AUTOSAR XML (schema 00044)
package /ComponentTypes
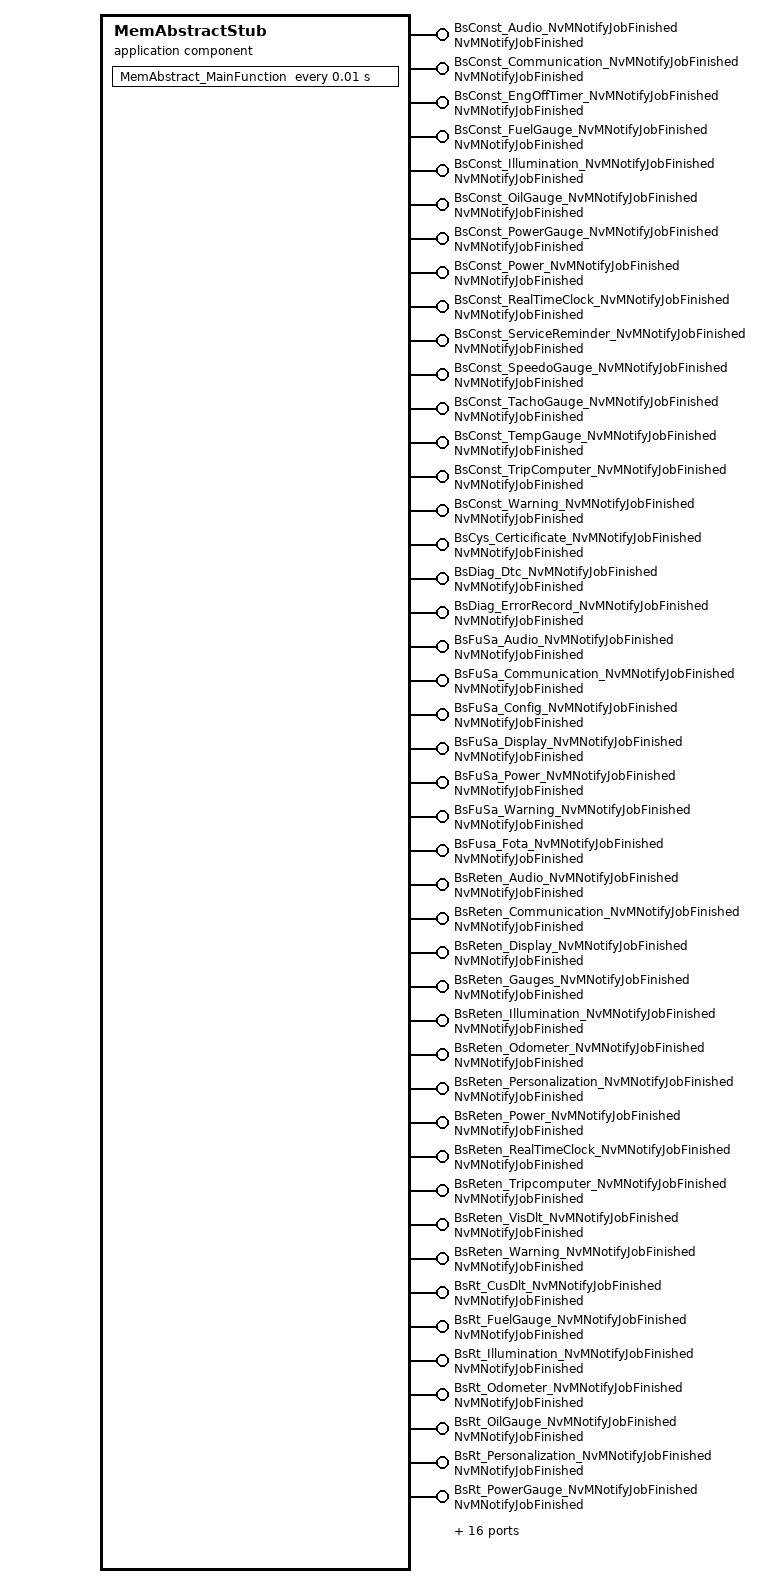
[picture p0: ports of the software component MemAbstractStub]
  application sw component type MemAbstractStub
    60 x provide port, all with server-com-spec{operation=JobFinished, queue-length=1}, provided-interface=NvMNotifyJobFinished:
      BsConst_Audio_NvMNotifyJobFinished
      BsConst_Communication_NvMNotifyJobFinished
      BsConst_EngOffTimer_NvMNotifyJobFinished
      BsConst_FuelGauge_NvMNotifyJobFinished
      BsConst_Illumination_NvMNotifyJobFinished
      BsConst_OilGauge_NvMNotifyJobFinished
      BsConst_PowerGauge_NvMNotifyJobFinished
      BsConst_Power_NvMNotifyJobFinished
      BsConst_RealTimeClock_NvMNotifyJobFinished
      BsConst_ServiceReminder_NvMNotifyJobFinished
      BsConst_SpeedoGauge_NvMNotifyJobFinished
      BsConst_TachoGauge_NvMNotifyJobFinished
      BsConst_TempGauge_NvMNotifyJobFinished
      BsConst_TripComputer_NvMNotifyJobFinished
      BsConst_Warning_NvMNotifyJobFinished
      BsCys_Certicificate_NvMNotifyJobFinished
      BsDiag_Dtc_NvMNotifyJobFinished
      BsDiag_ErrorRecord_NvMNotifyJobFinished
      BsFuSa_Audio_NvMNotifyJobFinished
      BsFuSa_Communication_NvMNotifyJobFinished
      BsFuSa_Config_NvMNotifyJobFinished
      BsFuSa_Display_NvMNotifyJobFinished
      BsFuSa_Power_NvMNotifyJobFinished
      BsFuSa_Warning_NvMNotifyJobFinished
      BsFusa_Fota_NvMNotifyJobFinished
      BsReten_Audio_NvMNotifyJobFinished
      BsReten_Communication_NvMNotifyJobFinished
      BsReten_Display_NvMNotifyJobFinished
      BsReten_Gauges_NvMNotifyJobFinished
      BsReten_Illumination_NvMNotifyJobFinished
      BsReten_Odometer_NvMNotifyJobFinished
      BsReten_Personalization_NvMNotifyJobFinished
      BsReten_Power_NvMNotifyJobFinished
      BsReten_RealTimeClock_NvMNotifyJobFinished
      BsReten_Tripcomputer_NvMNotifyJobFinished
      BsReten_VisDlt_NvMNotifyJobFinished
      BsReten_Warning_NvMNotifyJobFinished
      BsRt_CusDlt_NvMNotifyJobFinished
      BsRt_FuelGauge_NvMNotifyJobFinished
      BsRt_Illumination_NvMNotifyJobFinished
      BsRt_Odometer_NvMNotifyJobFinished
      BsRt_OilGauge_NvMNotifyJobFinished
      BsRt_Personalization_NvMNotifyJobFinished
      BsRt_PowerGauge_NvMNotifyJobFinished
      BsRt_RealTimeClock_NvMNotifyJobFinished
      BsRt_SpeedoGauge_NvMNotifyJobFinished
      BsRt_TachoGauge_NvMNotifyJobFinished
      BsRt_TempGauge_NvMNotifyJobFinished
      BsRt_TripComputer_NvMNotifyJobFinished
      BsRt_Warning_NvMNotifyJobFinished
      BsShare_EcuPartNumber_NvMNotifyJobFinished
      BsShare_SwUpdFotaFinPrint_NvMNotifyJobFinished
      BsShare_SwUpdFotaMode_NvMNotifyJobFinished
      BsShare_SwUpdFotaStatus_NvMNotifyJobFinished
      BsShare_SwUpdFotadecrypt_NvMNotifyJobFinished
      BsShare_SwUpdReflash_NvMNotifyJobFinished
      BsShare_VehicleConfig_NvMNotifyJobFinished
      BsShare_VisMeet_NvMNotifyJobFinished
      RefCys_Certicificate1_NvMNotifyJobFinished
      RefCys_Certicificate_NvMNotifyJobFinished
    60 x provide/require port:
      BsConst_PowerGauge_Element: nv-provide-com-spec{ram-block-init-value=64 x 0, rom-block-init-value=64 x 0, variable=Value}, nv-require-com-spec{init-value=64 x 0, variable=Value}, provided-required-interface=BsConst_PowerGauge_Element
      BsFuSa_Audio_Element: nv-provide-com-spec{ram-block-init-value=32 x 0, rom-block-init-value=32 x 0, variable=Value}, nv-require-com-spec{init-value=32 x 0, variable=Value}, provided-required-interface=BsFuSa_Audio_Element
      BsReten_Odometer_Element: nv-provide-com-spec{ram-block-init-value=100 x 0, rom-block-init-value=100 x 0, variable=Value}, nv-require-com-spec{init-value=100 x 0, variable=Value}, provided-required-interface=BsReten_Odometer_Element
      BsDiag_ErrorRecord_Element: nv-provide-com-spec{ram-block-init-value=1024 x 0, rom-block-init-value=1024 x 0, variable=Value}, nv-require-com-spec{init-value=1024 x 0, variable=Value}, provided-required-interface=BsDiag_ErrorRecord_Element
      BsConst_Audio_Element: nv-provide-com-spec{ram-block-init-value=128 x 0, rom-block-init-value=128 x 0, variable=Value}, nv-require-com-spec{init-value=128 x 0, variable=Value}, provided-required-interface=BsConst_Audio_Element
      BsConst_TempGauge_Element: nv-provide-com-spec{ram-block-init-value=64 x 0, rom-block-init-value=64 x 0, variable=Value}, nv-require-com-spec{init-value=64 x 0, variable=Value}, provided-required-interface=BsConst_TempGauge_Element
      BsFuSa_Communication_Element: nv-provide-com-spec{ram-block-init-value=16 x 0, rom-block-init-value=16 x 0, variable=Value}, nv-require-com-spec{init-value=16 x 0, variable=Value}, provided-required-interface=BsFuSa_Communication_Element
      BsRt_CusDlt_Element: nv-provide-com-spec{ram-block-init-value=128 x 0, rom-block-init-value=128 x 0, variable=Value}, nv-require-com-spec{init-value=128 x 0, variable=Value}, provided-required-interface=BsRt_CusDlt_Element
      BsShare_SwUpdFotaFinPrint_Element: nv-provide-com-spec{ram-block-init-value=32 x 0, rom-block-init-value=32 x 0, variable=Value}, nv-require-com-spec{init-value=32 x 0, variable=Value}, provided-required-interface=BsShare_SwUpdFotaFinPrint_Element
      BsConst_Power_Element: nv-provide-com-spec{ram-block-init-value=32 x 0, rom-block-init-value=32 x 0, variable=Value}, nv-require-com-spec{init-value=32 x 0, variable=Value}, provided-required-interface=BsConst_Power_Element
      BsRt_Illumination_Element: nv-provide-com-spec{ram-block-init-value=100 x 0, rom-block-init-value=100 x 0, variable=Value}, nv-require-com-spec{init-value=100 x 0, variable=Value}, provided-required-interface=BsRt_Illumination_Element
      BsReten_Gauges_Element: nv-provide-com-spec{ram-block-init-value=100 x 0, rom-block-init-value=100 x 0, variable=Value}, nv-require-com-spec{init-value=100 x 0, variable=Value}, provided-required-interface=BsReten_Gauges_Element
      BsCys_Certicificate_Element: nv-provide-com-spec{ram-block-init-value=64 x 0, rom-block-init-value=64 x 0, variable=Value}, nv-require-com-spec{init-value=64 x 0, variable=Value}, provided-required-interface=BsCys_Certicificate_Element
      BsConst_Communication_Element: nv-provide-com-spec{ram-block-init-value=64 x 0, rom-block-init-value=64 x 0, variable=Value}, nv-require-com-spec{init-value=64 x 0, variable=Value}, provided-required-interface=BsConst_Communication_Element
      BsShare_EcuPartNumber_Element: nv-provide-com-spec{ram-block-init-value=128 x 0, rom-block-init-value=128 x 0, variable=Value}, nv-require-com-spec{init-value=128 x 0, variable=Value}, provided-required-interface=BsShare_EcuPartNumber_Element
      BsShare_SwUpdFotaStatus_Element: nv-provide-com-spec{ram-block-init-value=48 x 0, rom-block-init-value=48 x 0, variable=Value}, nv-require-com-spec{init-value=48 x 0, variable=Value}, provided-required-interface=BsShare_SwUpdFotaStatus_Element
      RefCys_Certicificate_Element: nv-provide-com-spec{ram-block-init-value=64 x 0, rom-block-init-value=64 x 0, variable=Value}, nv-require-com-spec{init-value=64 x 0, variable=Value}, provided-required-interface=RefCys_Certicificate_Element
      BsReten_Audio_Element: nv-provide-com-spec{ram-block-init-value=100 x 0, rom-block-init-value=100 x 0, variable=Value}, nv-require-com-spec{init-value=100 x 0, variable=Value}, provided-required-interface=BsReten_Audio_Element
      BsConst_OilGauge_Element: nv-provide-com-spec{ram-block-init-value=64 x 0, rom-block-init-value=64 x 0, variable=Value}, nv-require-com-spec{init-value=64 x 0, variable=Value}, provided-required-interface=BsConst_OilGauge_Element
      BsConst_TripComputer_Element: nv-provide-com-spec{ram-block-init-value=64 x 0, rom-block-init-value=64 x 0, variable=Value}, nv-require-com-spec{init-value=64 x 0, variable=Value}, provided-required-interface=BsConst_TripComputer_Element
      BsConst_FuelGauge_Element: nv-provide-com-spec{ram-block-init-value=128 x 0, rom-block-init-value=128 x 0, variable=Value}, nv-require-com-spec{init-value=128 x 0, variable=Value}, provided-required-interface=BsConst_FuelGauge_Element
      BsFusa_Fota_Element: nv-provide-com-spec{ram-block-init-value=32 x 0, rom-block-init-value=32 x 0, variable=Value}, nv-require-com-spec{init-value=32 x 0, variable=Value}, provided-required-interface=BsFusa_Fota_Element
      BsReten_Illumination_Element: nv-provide-com-spec{ram-block-init-value=100 x 0, rom-block-init-value=100 x 0, variable=Value}, nv-require-com-spec{init-value=100 x 0, variable=Value}, provided-required-interface=BsReten_Illumination_Element
      BsRt_PowerGauge_Element: nv-provide-com-spec{ram-block-init-value=32 x 0, rom-block-init-value=32 x 0, variable=Value}, nv-require-com-spec{init-value=32 x 0, variable=Value}, provided-required-interface=BsRt_PowerGauge_Element
      BsReten_Tripcomputer_Element: nv-provide-com-spec{ram-block-init-value=100 x 0, rom-block-init-value=100 x 0, variable=Value}, nv-require-com-spec{init-value=100 x 0, variable=Value}, provided-required-interface=BsReten_Tripcomputer_Element
      BsFuSa_Display_Element: nv-provide-com-spec{ram-block-init-value=64 x 0, rom-block-init-value=64 x 0, variable=Value}, nv-require-com-spec{init-value=64 x 0, variable=Value}, provided-required-interface=BsFuSa_Display_Element
      BsReten_Power_Element: nv-provide-com-spec{ram-block-init-value=100 x 0, rom-block-init-value=100 x 0, variable=Value}, nv-require-com-spec{init-value=100 x 0, variable=Value}, provided-required-interface=BsReten_Power_Element
      BsShare_SwUpdReflash_Element: nv-provide-com-spec{ram-block-init-value=8 x 0, rom-block-init-value=8 x 0, variable=Value}, nv-require-com-spec{init-value=8 x 0, variable=Value}, provided-required-interface=BsShare_SwUpdReflash_Element
      BsRt_Odometer_Element: nv-provide-com-spec{ram-block-init-value=128 x 0, rom-block-init-value=128 x 0, variable=Value}, nv-require-com-spec{init-value=128 x 0, variable=Value}, provided-required-interface=BsRt_Odometer_Element
      BsShare_SwUpdFotadecrypt_Element: nv-provide-com-spec{ram-block-init-value=64 x 0, rom-block-init-value=64 x 0, variable=Value}, nv-require-com-spec{init-value=64 x 0, variable=Value}, provided-required-interface=BsShare_SwUpdFotadecrypt_Element
      BsConst_EngOffTimer_Element: nv-provide-com-spec{ram-block-init-value=32 x 0, rom-block-init-value=32 x 0, variable=Value}, nv-require-com-spec{init-value=32 x 0, variable=Value}, provided-required-interface=BsConst_EngOffTimer_Element
      BsReten_RealTimeClock_Element: nv-provide-com-spec{ram-block-init-value=100 x 0, rom-block-init-value=100 x 0, variable=Value}, nv-require-com-spec{init-value=100 x 0, variable=Value}, provided-required-interface=BsReten_RealTimeClock_Element
      BsRt_SpeedoGauge_Element: nv-provide-com-spec{ram-block-init-value=8 x 0, rom-block-init-value=8 x 0, variable=Value}, nv-require-com-spec{init-value=8 x 0, variable=Value}, provided-required-interface=BsRt_SpeedoGauge_Element
      BsReten_Display_Element: nv-provide-com-spec{ram-block-init-value=100 x 0, rom-block-init-value=100 x 0, variable=Value}, nv-require-com-spec{init-value=100 x 0, variable=Value}, provided-required-interface=BsReten_Display_Element
      BsConst_RealTimeClock_Element: nv-provide-com-spec{ram-block-init-value=48 x 0, rom-block-init-value=48 x 0, variable=Value}, nv-require-com-spec{init-value=48 x 0, variable=Value}, provided-required-interface=BsConst_RealTimeClock_Element
      BsReten_VisDlt_Element: nv-provide-com-spec{ram-block-init-value=256 x 0, rom-block-init-value=256 x 0, variable=Value}, nv-require-com-spec{init-value=256 x 0, variable=Value}, provided-required-interface=BsReten_VisDlt_Element
      BsRt_Warning_Element: nv-provide-com-spec{ram-block-init-value=32 x 0, rom-block-init-value=32 x 0, variable=Value}, nv-require-com-spec{init-value=32 x 0, variable=Value}, provided-required-interface=BsRt_Warning_Element
      BsRt_TripComputer_Element: nv-provide-com-spec{ram-block-init-value=64 x 0, rom-block-init-value=64 x 0, variable=Value}, nv-require-com-spec{init-value=64 x 0, variable=Value}, provided-required-interface=BsRt_TripComputer_Element
      BsDiag_Dtc_Element: nv-provide-com-spec{ram-block-init-value=2048 x 0, rom-block-init-value=2048 x 0, variable=Value}, nv-require-com-spec{init-value=2048 x 0, variable=Value}, provided-required-interface=BsDiag_Dtc_Element
      BsConst_Illumination_Element: nv-provide-com-spec{ram-block-init-value=128 x 0, rom-block-init-value=128 x 0, variable=Value}, nv-require-com-spec{init-value=128 x 0, variable=Value}, provided-required-interface=BsConst_Illumination_Element
      BsShare_VehicleConfig_Element: nv-provide-com-spec{ram-block-init-value=256 x 0, rom-block-init-value=256 x 0, variable=Value}, nv-require-com-spec{init-value=256 x 0, variable=Value}, provided-required-interface=BsShare_VehicleConfig_Element
      BsRt_Personalization_Element: nv-provide-com-spec{ram-block-init-value=128 x 0, rom-block-init-value=128 x 0, variable=Value}, nv-require-com-spec{init-value=128 x 0, variable=Value}, provided-required-interface=BsRt_Personalization_Element
      BsFuSa_Config_Element: nv-provide-com-spec{ram-block-init-value=16 x 0, rom-block-init-value=16 x 0, variable=Value}, nv-require-com-spec{init-value=16 x 0, variable=Value}, provided-required-interface=BsFuSa_Config_Element
      BsRt_TachoGauge_Element: nv-provide-com-spec{ram-block-init-value=16 x 0, rom-block-init-value=16 x 0, variable=Value}, nv-require-com-spec{init-value=16 x 0, variable=Value}, provided-required-interface=BsRt_TachoGauge_Element
      RefCys_Certicificate1_Element: nv-provide-com-spec{ram-block-init-value=64 x 0, rom-block-init-value=64 x 0, variable=Value}, nv-require-com-spec{init-value=64 x 0, variable=Value}, provided-required-interface=RefCys_Certicificate1_Element
      BsShare_VisMeet_Element: nv-provide-com-spec{ram-block-init-value=48 x 0, rom-block-init-value=48 x 0, variable=Value}, nv-require-com-spec{init-value=48 x 0, variable=Value}, provided-required-interface=BsShare_VisMeet_Element
      BsReten_Communication_Element: nv-provide-com-spec{ram-block-init-value=100 x 0, rom-block-init-value=100 x 0, variable=Value}, nv-require-com-spec{init-value=100 x 0, variable=Value}, provided-required-interface=BsReten_Communication_Element
      BsRt_FuelGauge_Element: nv-provide-com-spec{ram-block-init-value=32 x 0, rom-block-init-value=32 x 0, variable=Value}, nv-require-com-spec{init-value=32 x 0, variable=Value}, provided-required-interface=BsRt_FuelGauge_Element
      BsConst_Warning_Element: nv-provide-com-spec{ram-block-init-value=64 x 0, rom-block-init-value=64 x 0, variable=Value}, nv-require-com-spec{init-value=64 x 0, variable=Value}, provided-required-interface=BsConst_Warning_Element
      BsConst_SpeedoGauge_Element: nv-provide-com-spec{ram-block-init-value=64 x 0, rom-block-init-value=64 x 0, variable=Value}, nv-require-com-spec{init-value=64 x 0, variable=Value}, provided-required-interface=BsConst_SpeedoGauge_Element
      BsReten_Personalization_Element: nv-provide-com-spec{ram-block-init-value=100 x 0, rom-block-init-value=100 x 0, variable=Value}, nv-require-com-spec{init-value=100 x 0, variable=Value}, provided-required-interface=BsReten_Personalization_Element
      BsRt_RealTimeClock_Element: nv-provide-com-spec{ram-block-init-value=48 x 0, rom-block-init-value=48 x 0, variable=Value}, nv-require-com-spec{init-value=48 x 0, variable=Value}, provided-required-interface=BsRt_RealTimeClock_Element
      BsConst_TachoGauge_Element: nv-provide-com-spec{ram-block-init-value=64 x 0, rom-block-init-value=64 x 0, variable=Value}, nv-require-com-spec{init-value=64 x 0, variable=Value}, provided-required-interface=BsConst_TachoGauge_Element
      BsRt_OilGauge_Element: nv-provide-com-spec{ram-block-init-value=8 x 0, rom-block-init-value=8 x 0, variable=Value}, nv-require-com-spec{init-value=8 x 0, variable=Value}, provided-required-interface=BsRt_OilGauge_Element
      BsConst_ServiceReminder_Element: nv-provide-com-spec{ram-block-init-value=48 x 0, rom-block-init-value=48 x 0, variable=Value}, nv-require-com-spec{init-value=48 x 0, variable=Value}, provided-required-interface=BsConst_ServiceReminder_Element
      BsFuSa_Power_Element: nv-provide-com-spec{ram-block-init-value=48 x 0, rom-block-init-value=48 x 0, variable=Value}, nv-require-com-spec{init-value=48 x 0, variable=Value}, provided-required-interface=BsFuSa_Power_Element
      BsFuSa_Warning_Element: nv-provide-com-spec{ram-block-init-value=32 x 0, rom-block-init-value=32 x 0, variable=Value}, nv-require-com-spec{init-value=32 x 0, variable=Value}, provided-required-interface=BsFuSa_Warning_Element
      BsRt_TempGauge_Element: nv-provide-com-spec{ram-block-init-value=32 x 0, rom-block-init-value=32 x 0, variable=Value}, nv-require-com-spec{init-value=32 x 0, variable=Value}, provided-required-interface=BsRt_TempGauge_Element
      BsShare_SwUpdFotaMode_Element: nv-provide-com-spec{ram-block-init-value=16 x 0, rom-block-init-value=16 x 0, variable=Value}, nv-require-com-spec{init-value=16 x 0, variable=Value}, provided-required-interface=BsShare_SwUpdFotaMode_Element
      BsReten_Warning_Element: nv-provide-com-spec{ram-block-init-value=100 x 0, rom-block-init-value=100 x 0, variable=Value}, nv-require-com-spec{init-value=100 x 0, variable=Value}, provided-required-interface=BsReten_Warning_Element
    behavior MemAbstractStub_InternalBehavior
      timing event TMT_MemAbstract_MainFunction: start-on-event=MemAbstract_MainFunction, period=0.01
      60 x operation invoked event:
        OIT_MemAbstractMdl_NotifyJobEnd_BsConst_Audio_NvMNotifyJobFinished_JobFinished: start-on-event=MemAbstractMdl_NotifyJobEnd_BsConst_Audio, operation=BsConst_Audio_NvMNotifyJobFinished.JobFinished
        OIT_MemAbstractMdl_NotifyJobEnd_BsConst_Communication_NvMNotifyJobFinished_JobFinished: start-on-event=MemAbstractMdl_NotifyJobEnd_BsConst_Communication, operation=BsConst_Communication_NvMNotifyJobFinished.JobFinished
        OIT_MemAbstractMdl_NotifyJobEnd_BsConst_EngOffTimer_NvMNotifyJobFinished_JobFinished: start-on-event=MemAbstractMdl_NotifyJobEnd_BsConst_EngOffTimer, operation=BsConst_EngOffTimer_NvMNotifyJobFinished.JobFinished
        OIT_MemAbstractMdl_NotifyJobEnd_BsConst_FuelGauge_NvMNotifyJobFinished_JobFinished: start-on-event=MemAbstractMdl_NotifyJobEnd_BsConst_FuelGauge, operation=BsConst_FuelGauge_NvMNotifyJobFinished.JobFinished
        OIT_MemAbstractMdl_NotifyJobEnd_BsConst_Illumination_NvMNotifyJobFinished_JobFinished: start-on-event=MemAbstractMdl_NotifyJobEnd_BsConst_Illumination, operation=BsConst_Illumination_NvMNotifyJobFinished.JobFinished
        OIT_MemAbstractMdl_NotifyJobEnd_BsConst_OilGauge_NvMNotifyJobFinished_JobFinished: start-on-event=MemAbstractMdl_NotifyJobEnd_BsConst_OilGauge, operation=BsConst_OilGauge_NvMNotifyJobFinished.JobFinished
        OIT_MemAbstractMdl_NotifyJobEnd_BsConst_Power_NvMNotifyJobFinished_JobFinished: start-on-event=MemAbstractMdl_NotifyJobEnd_BsConst_Power, operation=BsConst_Power_NvMNotifyJobFinished.JobFinished
        OIT_MemAbstractMdl_NotifyJobEnd_BsConst_PowerGauge_NvMNotifyJobFinished_JobFinished: start-on-event=MemAbstractMdl_NotifyJobEnd_BsConst_PowerGauge, operation=BsConst_PowerGauge_NvMNotifyJobFinished.JobFinished
        OIT_MemAbstractMdl_NotifyJobEnd_BsConst_RealTimeClock_NvMNotifyJobFinished_JobFinished: start-on-event=MemAbstractMdl_NotifyJobEnd_BsConst_RealTimeClock, operation=BsConst_RealTimeClock_NvMNotifyJobFinished.JobFinished
        OIT_MemAbstractMdl_NotifyJobEnd_BsConst_ServiceReminder_NvMNotifyJobFinished_JobFinished: start-on-event=MemAbstractMdl_NotifyJobEnd_BsConst_ServiceReminder, operation=BsConst_ServiceReminder_NvMNotifyJobFinished.JobFinished
        OIT_MemAbstractMdl_NotifyJobEnd_BsConst_SpeedoGauge_NvMNotifyJobFinished_JobFinished: start-on-event=MemAbstractMdl_NotifyJobEnd_BsConst_SpeedoGauge, operation=BsConst_SpeedoGauge_NvMNotifyJobFinished.JobFinished
        OIT_MemAbstractMdl_NotifyJobEnd_BsConst_TachoGauge_NvMNotifyJobFinished_JobFinished: start-on-event=MemAbstractMdl_NotifyJobEnd_BsConst_TachoGauge, operation=BsConst_TachoGauge_NvMNotifyJobFinished.JobFinished
        OIT_MemAbstractMdl_NotifyJobEnd_BsConst_TempGauge_NvMNotifyJobFinished_JobFinished: start-on-event=MemAbstractMdl_NotifyJobEnd_BsConst_TempGauge, operation=BsConst_TempGauge_NvMNotifyJobFinished.JobFinished
        OIT_MemAbstractMdl_NotifyJobEnd_BsConst_TripComputer_NvMNotifyJobFinished_JobFinished: start-on-event=MemAbstractMdl_NotifyJobEnd_BsConst_TripComputer, operation=BsConst_TripComputer_NvMNotifyJobFinished.JobFinished
        OIT_MemAbstractMdl_NotifyJobEnd_BsConst_Warning_NvMNotifyJobFinished_JobFinished: start-on-event=MemAbstractMdl_NotifyJobEnd_BsConst_Warning, operation=BsConst_Warning_NvMNotifyJobFinished.JobFinished
        OIT_MemAbstractMdl_NotifyJobEnd_BsCys_Certicificate_NvMNotifyJobFinished_JobFinished: start-on-event=MemAbstractMdl_NotifyJobEnd_BsCys_Certicificate, operation=BsCys_Certicificate_NvMNotifyJobFinished.JobFinished
        OIT_MemAbstractMdl_NotifyJobEnd_BsDiag_Dtc_NvMNotifyJobFinished_JobFinished: start-on-event=MemAbstractMdl_NotifyJobEnd_BsDiag_Dtc, operation=BsDiag_Dtc_NvMNotifyJobFinished.JobFinished
        OIT_MemAbstractMdl_NotifyJobEnd_BsDiag_ErrorRecord_NvMNotifyJobFinished_JobFinished: start-on-event=MemAbstractMdl_NotifyJobEnd_BsDiag_ErrorRecord, operation=BsDiag_ErrorRecord_NvMNotifyJobFinished.JobFinished
        OIT_MemAbstractMdl_NotifyJobEnd_BsFuSa_Audio_NvMNotifyJobFinished_JobFinished: start-on-event=MemAbstractMdl_NotifyJobEnd_BsFuSa_Audio, operation=BsFuSa_Audio_NvMNotifyJobFinished.JobFinished
        OIT_MemAbstractMdl_NotifyJobEnd_BsFuSa_Communication_NvMNotifyJobFinished_JobFinished: start-on-event=MemAbstractMdl_NotifyJobEnd_BsFuSa_Communication, operation=BsFuSa_Communication_NvMNotifyJobFinished.JobFinished
        OIT_MemAbstractMdl_NotifyJobEnd_BsFuSa_Config_NvMNotifyJobFinished_JobFinished: start-on-event=MemAbstractMdl_NotifyJobEnd_BsFuSa_Config, operation=BsFuSa_Config_NvMNotifyJobFinished.JobFinished
        OIT_MemAbstractMdl_NotifyJobEnd_BsFuSa_Display_NvMNotifyJobFinished_JobFinished: start-on-event=MemAbstractMdl_NotifyJobEnd_BsFuSa_Display, operation=BsFuSa_Display_NvMNotifyJobFinished.JobFinished
        OIT_MemAbstractMdl_NotifyJobEnd_BsFuSa_Power_NvMNotifyJobFinished_JobFinished: start-on-event=MemAbstractMdl_NotifyJobEnd_BsFuSa_Power, operation=BsFuSa_Power_NvMNotifyJobFinished.JobFinished
        OIT_MemAbstractMdl_NotifyJobEnd_BsFuSa_Warning_NvMNotifyJobFinished_JobFinished: start-on-event=MemAbstractMdl_NotifyJobEnd_BsFuSa_Warning, operation=BsFuSa_Warning_NvMNotifyJobFinished.JobFinished
        OIT_MemAbstractMdl_NotifyJobEnd_BsFusa_Fota_NvMNotifyJobFinished_JobFinished: start-on-event=MemAbstractMdl_NotifyJobEnd_BsFusa_Fota, operation=BsFusa_Fota_NvMNotifyJobFinished.JobFinished
        OIT_MemAbstractMdl_NotifyJobEnd_BsReten_Audio_NvMNotifyJobFinished_JobFinished: start-on-event=MemAbstractMdl_NotifyJobEnd_BsReten_Audio, operation=BsReten_Audio_NvMNotifyJobFinished.JobFinished
        OIT_MemAbstractMdl_NotifyJobEnd_BsReten_Communication_NvMNotifyJobFinished_JobFinished: start-on-event=MemAbstractMdl_NotifyJobEnd_BsReten_Communication, operation=BsReten_Communication_NvMNotifyJobFinished.JobFinished
        OIT_MemAbstractMdl_NotifyJobEnd_BsReten_Display_NvMNotifyJobFinished_JobFinished: start-on-event=MemAbstractMdl_NotifyJobEnd_BsReten_Display, operation=BsReten_Display_NvMNotifyJobFinished.JobFinished
        OIT_MemAbstractMdl_NotifyJobEnd_BsReten_Gauges_NvMNotifyJobFinished_JobFinished: start-on-event=MemAbstractMdl_NotifyJobEnd_BsReten_Gauges, operation=BsReten_Gauges_NvMNotifyJobFinished.JobFinished
        OIT_MemAbstractMdl_NotifyJobEnd_BsReten_Illumination_NvMNotifyJobFinished_JobFinished: start-on-event=MemAbstractMdl_NotifyJobEnd_BsReten_Illumination, operation=BsReten_Illumination_NvMNotifyJobFinished.JobFinished
        OIT_MemAbstractMdl_NotifyJobEnd_BsReten_Odometer_NvMNotifyJobFinished_JobFinished: start-on-event=MemAbstractMdl_NotifyJobEnd_BsReten_Odometer, operation=BsReten_Odometer_NvMNotifyJobFinished.JobFinished
        OIT_MemAbstractMdl_NotifyJobEnd_BsReten_Personalization_NvMNotifyJobFinished_JobFinished: start-on-event=MemAbstractMdl_NotifyJobEnd_BsReten_Personalization, operation=BsReten_Personalization_NvMNotifyJobFinished.JobFinished
        OIT_MemAbstractMdl_NotifyJobEnd_BsReten_Power_NvMNotifyJobFinished_JobFinished: start-on-event=MemAbstractMdl_NotifyJobEnd_BsReten_Power, operation=BsReten_Power_NvMNotifyJobFinished.JobFinished
        OIT_MemAbstractMdl_NotifyJobEnd_BsReten_RealTimeClock_NvMNotifyJobFinished_JobFinished: start-on-event=MemAbstractMdl_NotifyJobEnd_BsReten_RealTimeClock, operation=BsReten_RealTimeClock_NvMNotifyJobFinished.JobFinished
        OIT_MemAbstractMdl_NotifyJobEnd_BsReten_Tripcomputer_NvMNotifyJobFinished_JobFinished: start-on-event=MemAbstractMdl_NotifyJobEnd_BsReten_Tripcomputer, operation=BsReten_Tripcomputer_NvMNotifyJobFinished.JobFinished
        OIT_MemAbstractMdl_NotifyJobEnd_BsReten_VisDlt_NvMNotifyJobFinished_JobFinished: start-on-event=MemAbstractMdl_NotifyJobEnd_BsReten_VisDlt, operation=BsReten_VisDlt_NvMNotifyJobFinished.JobFinished
        OIT_MemAbstractMdl_NotifyJobEnd_BsReten_Warning_NvMNotifyJobFinished_JobFinished: start-on-event=MemAbstractMdl_NotifyJobEnd_BsReten_Warning, operation=BsReten_Warning_NvMNotifyJobFinished.JobFinished
        OIT_MemAbstractMdl_NotifyJobEnd_BsRt_CusDlt_NvMNotifyJobFinished_JobFinished: start-on-event=MemAbstractMdl_NotifyJobEnd_BsRt_CusDlt, operation=BsRt_CusDlt_NvMNotifyJobFinished.JobFinished
        OIT_MemAbstractMdl_NotifyJobEnd_BsRt_FuelGauge_NvMNotifyJobFinished_JobFinished: start-on-event=MemAbstractMdl_NotifyJobEnd_BsRt_FuelGauge, operation=BsRt_FuelGauge_NvMNotifyJobFinished.JobFinished
        OIT_MemAbstractMdl_NotifyJobEnd_BsRt_Illumination_NvMNotifyJobFinished_JobFinished: start-on-event=MemAbstractMdl_NotifyJobEnd_BsRt_Illumination, operation=BsRt_Illumination_NvMNotifyJobFinished.JobFinished
        OIT_MemAbstractMdl_NotifyJobEnd_BsRt_Odometer_NvMNotifyJobFinished_JobFinished: start-on-event=MemAbstractMdl_NotifyJobEnd_BsRt_Odometer, operation=BsRt_Odometer_NvMNotifyJobFinished.JobFinished
        OIT_MemAbstractMdl_NotifyJobEnd_BsRt_OilGauge_NvMNotifyJobFinished_JobFinished: start-on-event=MemAbstractMdl_NotifyJobEnd_BsRt_OilGauge, operation=BsRt_OilGauge_NvMNotifyJobFinished.JobFinished
        OIT_MemAbstractMdl_NotifyJobEnd_BsRt_Personalization_NvMNotifyJobFinished_JobFinished: start-on-event=MemAbstractMdl_NotifyJobEnd_BsRt_Personalization, operation=BsRt_Personalization_NvMNotifyJobFinished.JobFinished
        OIT_MemAbstractMdl_NotifyJobEnd_BsRt_PowerGauge_NvMNotifyJobFinished_JobFinished: start-on-event=MemAbstractMdl_NotifyJobEnd_BsRt_PowerGauge, operation=BsRt_PowerGauge_NvMNotifyJobFinished.JobFinished
        OIT_MemAbstractMdl_NotifyJobEnd_BsRt_RealTimeClock_NvMNotifyJobFinished_JobFinished: start-on-event=MemAbstractMdl_NotifyJobEnd_BsRt_RealTimeClock, operation=BsRt_RealTimeClock_NvMNotifyJobFinished.JobFinished
        OIT_MemAbstractMdl_NotifyJobEnd_BsRt_SpeedoGauge_NvMNotifyJobFinished_JobFinished: start-on-event=MemAbstractMdl_NotifyJobEnd_BsRt_SpeedoGauge, operation=BsRt_SpeedoGauge_NvMNotifyJobFinished.JobFinished
        OIT_MemAbstractMdl_NotifyJobEnd_BsRt_TachoGauge_NvMNotifyJobFinished_JobFinished: start-on-event=MemAbstractMdl_NotifyJobEnd_BsRt_TachoGauge, operation=BsRt_TachoGauge_NvMNotifyJobFinished.JobFinished
        OIT_MemAbstractMdl_NotifyJobEnd_BsRt_TempGauge_NvMNotifyJobFinished_JobFinished: start-on-event=MemAbstractMdl_NotifyJobEnd_BsRt_TempGauge, operation=BsRt_TempGauge_NvMNotifyJobFinished.JobFinished
        OIT_MemAbstractMdl_NotifyJobEnd_BsRt_TripComputer_NvMNotifyJobFinished_JobFinished: start-on-event=MemAbstractMdl_NotifyJobEnd_BsRt_TripComputer, operation=BsRt_TripComputer_NvMNotifyJobFinished.JobFinished
        OIT_MemAbstractMdl_NotifyJobEnd_BsRt_Warning_NvMNotifyJobFinished_JobFinished: start-on-event=MemAbstractMdl_NotifyJobEnd_BsRt_Warning, operation=BsRt_Warning_NvMNotifyJobFinished.JobFinished
        OIT_MemAbstractMdl_NotifyJobEnd_BsShare_EcuPartNumber_NvMNotifyJobFinished_JobFinished: start-on-event=MemAbstractMdl_NotifyJobEnd_BsShare_EcuPartNumber, operation=BsShare_EcuPartNumber_NvMNotifyJobFinished.JobFinished
        OIT_MemAbstractMdl_NotifyJobEnd_BsShare_SwUpdFotaFinPrint_NvMNotifyJobFinished_JobFinished: start-on-event=MemAbstractMdl_NotifyJobEnd_BsShare_SwUpdFotaFinPrint, operation=BsShare_SwUpdFotaFinPrint_NvMNotifyJobFinished.JobFinished
        OIT_MemAbstractMdl_NotifyJobEnd_BsShare_SwUpdFotaMode_NvMNotifyJobFinished_JobFinished: start-on-event=MemAbstractMdl_NotifyJobEnd_BsShare_SwUpdFotaMode, operation=BsShare_SwUpdFotaMode_NvMNotifyJobFinished.JobFinished
        OIT_MemAbstractMdl_NotifyJobEnd_BsShare_SwUpdFotaStatus_NvMNotifyJobFinished_JobFinished: start-on-event=MemAbstractMdl_NotifyJobEnd_BsShare_SwUpdFotaStatus, operation=BsShare_SwUpdFotaStatus_NvMNotifyJobFinished.JobFinished
        OIT_MemAbstractMdl_NotifyJobEnd_BsShare_SwUpdFotadecrypt_NvMNotifyJobFinished_JobFinished: start-on-event=MemAbstractMdl_NotifyJobEnd_BsShare_SwUpdFotadecrypt, operation=BsShare_SwUpdFotadecrypt_NvMNotifyJobFinished.JobFinished
        OIT_MemAbstractMdl_NotifyJobEnd_BsShare_SwUpdReflash_NvMNotifyJobFinished_JobFinished: start-on-event=MemAbstractMdl_NotifyJobEnd_BsShare_SwUpdReflash, operation=BsShare_SwUpdReflash_NvMNotifyJobFinished.JobFinished
        OIT_MemAbstractMdl_NotifyJobEnd_BsShare_VehicleConfig_NvMNotifyJobFinished_JobFinished: start-on-event=MemAbstractMdl_NotifyJobEnd_BsShare_VehicleConfig, operation=BsShare_VehicleConfig_NvMNotifyJobFinished.JobFinished
        OIT_MemAbstractMdl_NotifyJobEnd_BsShare_VisMeet_NvMNotifyJobFinished_JobFinished: start-on-event=MemAbstractMdl_NotifyJobEnd_BsShare_VisMeet, operation=BsShare_VisMeet_NvMNotifyJobFinished.JobFinished
        OIT_MemAbstractMdl_NotifyJobEnd_RefCys_Certicificate_NvMNotifyJobFinished_JobFinished: start-on-event=MemAbstractMdl_NotifyJobEnd_RefCys_Certicificate, operation=RefCys_Certicificate_NvMNotifyJobFinished.JobFinished
        OIT_MemAbstractMdl_NotifyJobEnd_RefCys_Certicificate1_NvMNotifyJobFinished_JobFinished: start-on-event=MemAbstractMdl_NotifyJobEnd_RefCys_Certicificate1, operation=RefCys_Certicificate1_NvMNotifyJobFinished.JobFinished
      61 x runnable:
        MemAbstract_MainFunction
          data-receive-point-by-arguments:
            60 x access:
              REC_BsConst_Audio_Element_Value: accessed-variable=BsConst_Audio_Element.Value
              REC_BsConst_Communication_Element_Value: accessed-variable=BsConst_Communication_Element.Value
              REC_BsConst_EngOffTimer_Element_Value: accessed-variable=BsConst_EngOffTimer_Element.Value
              REC_BsConst_FuelGauge_Element_Value: accessed-variable=BsConst_FuelGauge_Element.Value
              REC_BsConst_Illumination_Element_Value: accessed-variable=BsConst_Illumination_Element.Value
              REC_BsConst_OilGauge_Element_Value: accessed-variable=BsConst_OilGauge_Element.Value
              REC_BsConst_PowerGauge_Element_Value: accessed-variable=BsConst_PowerGauge_Element.Value
              REC_BsConst_Power_Element_Value: accessed-variable=BsConst_Power_Element.Value
              REC_BsConst_RealTimeClock_Element_Value: accessed-variable=BsConst_RealTimeClock_Element.Value
              REC_BsConst_ServiceReminder_Element_Value: accessed-variable=BsConst_ServiceReminder_Element.Value
              REC_BsConst_SpeedoGauge_Element_Value: accessed-variable=BsConst_SpeedoGauge_Element.Value
              REC_BsConst_TachoGauge_Element_Value: accessed-variable=BsConst_TachoGauge_Element.Value
              REC_BsConst_TempGauge_Element_Value: accessed-variable=BsConst_TempGauge_Element.Value
              REC_BsConst_TripComputer_Element_Value: accessed-variable=BsConst_TripComputer_Element.Value
              REC_BsConst_Warning_Element_Value: accessed-variable=BsConst_Warning_Element.Value
              REC_BsCys_Certicificate_Element_Value: accessed-variable=BsCys_Certicificate_Element.Value
              REC_BsDiag_Dtc_Element_Value: accessed-variable=BsDiag_Dtc_Element.Value
              REC_BsDiag_ErrorRecord_Element_Value: accessed-variable=BsDiag_ErrorRecord_Element.Value
              REC_BsFuSa_Audio_Element_Value: accessed-variable=BsFuSa_Audio_Element.Value
              REC_BsFuSa_Communication_Element_Value: accessed-variable=BsFuSa_Communication_Element.Value
              REC_BsFuSa_Config_Element_Value: accessed-variable=BsFuSa_Config_Element.Value
              REC_BsFuSa_Display_Element_Value: accessed-variable=BsFuSa_Display_Element.Value
              REC_BsFuSa_Power_Element_Value: accessed-variable=BsFuSa_Power_Element.Value
              REC_BsFuSa_Warning_Element_Value: accessed-variable=BsFuSa_Warning_Element.Value
              REC_BsFusa_Fota_Element_Value: accessed-variable=BsFusa_Fota_Element.Value
              REC_BsReten_Audio_Element_Value: accessed-variable=BsReten_Audio_Element.Value
              REC_BsReten_Communication_Element_Value: accessed-variable=BsReten_Communication_Element.Value
              REC_BsReten_Display_Element_Value: accessed-variable=BsReten_Display_Element.Value
              REC_BsReten_Gauges_Element_Value: accessed-variable=BsReten_Gauges_Element.Value
              REC_BsReten_Illumination_Element_Value: accessed-variable=BsReten_Illumination_Element.Value
              REC_BsReten_Odometer_Element_Value: accessed-variable=BsReten_Odometer_Element.Value
              REC_BsReten_Personalization_Element_Value: accessed-variable=BsReten_Personalization_Element.Value
              REC_BsReten_Power_Element_Value: accessed-variable=BsReten_Power_Element.Value
              REC_BsReten_RealTimeClock_Element_Value: accessed-variable=BsReten_RealTimeClock_Element.Value
              REC_BsReten_Tripcomputer_Element_Value: accessed-variable=BsReten_Tripcomputer_Element.Value
              REC_BsReten_VisDlt_Element_Value: accessed-variable=BsReten_VisDlt_Element.Value
              REC_BsReten_Warning_Element_Value: accessed-variable=BsReten_Warning_Element.Value
              REC_BsRt_CusDlt_Element_Value: accessed-variable=BsRt_CusDlt_Element.Value
              REC_BsRt_FuelGauge_Element_Value: accessed-variable=BsRt_FuelGauge_Element.Value
              REC_BsRt_Illumination_Element_Value: accessed-variable=BsRt_Illumination_Element.Value
              REC_BsRt_Odometer_Element_Value: accessed-variable=BsRt_Odometer_Element.Value
              REC_BsRt_OilGauge_Element_Value: accessed-variable=BsRt_OilGauge_Element.Value
              REC_BsRt_Personalization_Element_Value: accessed-variable=BsRt_Personalization_Element.Value
              REC_BsRt_PowerGauge_Element_Value: accessed-variable=BsRt_PowerGauge_Element.Value
              REC_BsRt_RealTimeClock_Element_Value: accessed-variable=BsRt_RealTimeClock_Element.Value
              REC_BsRt_SpeedoGauge_Element_Value: accessed-variable=BsRt_SpeedoGauge_Element.Value
              REC_BsRt_TachoGauge_Element_Value: accessed-variable=BsRt_TachoGauge_Element.Value
              REC_BsRt_TempGauge_Element_Value: accessed-variable=BsRt_TempGauge_Element.Value
              REC_BsRt_TripComputer_Element_Value: accessed-variable=BsRt_TripComputer_Element.Value
              REC_BsRt_Warning_Element_Value: accessed-variable=BsRt_Warning_Element.Value
              REC_BsShare_EcuPartNumber_Element_Value: accessed-variable=BsShare_EcuPartNumber_Element.Value
              REC_BsShare_SwUpdFotaFinPrint_Element_Value: accessed-variable=BsShare_SwUpdFotaFinPrint_Element.Value
              REC_BsShare_SwUpdFotaMode_Element_Value: accessed-variable=BsShare_SwUpdFotaMode_Element.Value
              REC_BsShare_SwUpdFotaStatus_Element_Value: accessed-variable=BsShare_SwUpdFotaStatus_Element.Value
              REC_BsShare_SwUpdFotadecrypt_Element_Value: accessed-variable=BsShare_SwUpdFotadecrypt_Element.Value
              REC_BsShare_SwUpdReflash_Element_Value: accessed-variable=BsShare_SwUpdReflash_Element.Value
              REC_BsShare_VehicleConfig_Element_Value: accessed-variable=BsShare_VehicleConfig_Element.Value
              REC_BsShare_VisMeet_Element_Value: accessed-variable=BsShare_VisMeet_Element.Value
              REC_RefCys_Certicificate1_Element_Value: accessed-variable=RefCys_Certicificate1_Element.Value
              REC_RefCys_Certicificate_Element_Value: accessed-variable=RefCys_Certicificate_Element.Value
          data-send-points:
            60 x access:
              SEND_BsConst_Audio_Element_Value: accessed-variable=BsConst_Audio_Element.Value
              SEND_BsConst_Communication_Element_Value: accessed-variable=BsConst_Communication_Element.Value
              SEND_BsConst_EngOffTimer_Element_Value: accessed-variable=BsConst_EngOffTimer_Element.Value
              SEND_BsConst_FuelGauge_Element_Value: accessed-variable=BsConst_FuelGauge_Element.Value
              SEND_BsConst_Illumination_Element_Value: accessed-variable=BsConst_Illumination_Element.Value
              SEND_BsConst_OilGauge_Element_Value: accessed-variable=BsConst_OilGauge_Element.Value
              SEND_BsConst_PowerGauge_Element_Value: accessed-variable=BsConst_PowerGauge_Element.Value
              SEND_BsConst_Power_Element_Value: accessed-variable=BsConst_Power_Element.Value
              SEND_BsConst_RealTimeClock_Element_Value: accessed-variable=BsConst_RealTimeClock_Element.Value
              SEND_BsConst_ServiceReminder_Element_Value: accessed-variable=BsConst_ServiceReminder_Element.Value
              SEND_BsConst_SpeedoGauge_Element_Value: accessed-variable=BsConst_SpeedoGauge_Element.Value
              SEND_BsConst_TachoGauge_Element_Value: accessed-variable=BsConst_TachoGauge_Element.Value
              SEND_BsConst_TempGauge_Element_Value: accessed-variable=BsConst_TempGauge_Element.Value
              SEND_BsConst_TripComputer_Element_Value: accessed-variable=BsConst_TripComputer_Element.Value
              SEND_BsConst_Warning_Element_Value: accessed-variable=BsConst_Warning_Element.Value
              SEND_BsCys_Certicificate_Element_Value: accessed-variable=BsCys_Certicificate_Element.Value
              SEND_BsDiag_Dtc_Element_Value: accessed-variable=BsDiag_Dtc_Element.Value
              SEND_BsDiag_ErrorRecord_Element_Value: accessed-variable=BsDiag_ErrorRecord_Element.Value
              SEND_BsFuSa_Audio_Element_Value: accessed-variable=BsFuSa_Audio_Element.Value
              SEND_BsFuSa_Communication_Element_Value: accessed-variable=BsFuSa_Communication_Element.Value
              SEND_BsFuSa_Config_Element_Value: accessed-variable=BsFuSa_Config_Element.Value
              SEND_BsFuSa_Display_Element_Value: accessed-variable=BsFuSa_Display_Element.Value
              SEND_BsFuSa_Power_Element_Value: accessed-variable=BsFuSa_Power_Element.Value
              SEND_BsFuSa_Warning_Element_Value: accessed-variable=BsFuSa_Warning_Element.Value
              SEND_BsFusa_Fota_Element_Value: accessed-variable=BsFusa_Fota_Element.Value
              SEND_BsReten_Audio_Element_Value: accessed-variable=BsReten_Audio_Element.Value
              SEND_BsReten_Communication_Element_Value: accessed-variable=BsReten_Communication_Element.Value
              SEND_BsReten_Display_Element_Value: accessed-variable=BsReten_Display_Element.Value
              SEND_BsReten_Gauges_Element_Value: accessed-variable=BsReten_Gauges_Element.Value
              SEND_BsReten_Illumination_Element_Value: accessed-variable=BsReten_Illumination_Element.Value
              SEND_BsReten_Odometer_Element_Value: accessed-variable=BsReten_Odometer_Element.Value
              SEND_BsReten_Personalization_Element_Value: accessed-variable=BsReten_Personalization_Element.Value
              SEND_BsReten_Power_Element_Value: accessed-variable=BsReten_Power_Element.Value
              SEND_BsReten_RealTimeClock_Element_Value: accessed-variable=BsReten_RealTimeClock_Element.Value
              SEND_BsReten_Tripcomputer_Element_Value: accessed-variable=BsReten_Tripcomputer_Element.Value
              SEND_BsReten_VisDlt_Element_Value: accessed-variable=BsReten_VisDlt_Element.Value
              SEND_BsReten_Warning_Element_Value: accessed-variable=BsReten_Warning_Element.Value
              SEND_BsRt_CusDlt_Element_Value: accessed-variable=BsRt_CusDlt_Element.Value
              SEND_BsRt_FuelGauge_Element_Value: accessed-variable=BsRt_FuelGauge_Element.Value
              SEND_BsRt_Illumination_Element_Value: accessed-variable=BsRt_Illumination_Element.Value
              SEND_BsRt_Odometer_Element_Value: accessed-variable=BsRt_Odometer_Element.Value
              SEND_BsRt_OilGauge_Element_Value: accessed-variable=BsRt_OilGauge_Element.Value
              SEND_BsRt_Personalization_Element_Value: accessed-variable=BsRt_Personalization_Element.Value
              SEND_BsRt_PowerGauge_Element_Value: accessed-variable=BsRt_PowerGauge_Element.Value
              SEND_BsRt_RealTimeClock_Element_Value: accessed-variable=BsRt_RealTimeClock_Element.Value
              SEND_BsRt_SpeedoGauge_Element_Value: accessed-variable=BsRt_SpeedoGauge_Element.Value
              SEND_BsRt_TachoGauge_Element_Value: accessed-variable=BsRt_TachoGauge_Element.Value
              SEND_BsRt_TempGauge_Element_Value: accessed-variable=BsRt_TempGauge_Element.Value
              SEND_BsRt_TripComputer_Element_Value: accessed-variable=BsRt_TripComputer_Element.Value
              SEND_BsRt_Warning_Element_Value: accessed-variable=BsRt_Warning_Element.Value
              SEND_BsShare_EcuPartNumber_Element_Value: accessed-variable=BsShare_EcuPartNumber_Element.Value
              SEND_BsShare_SwUpdFotaFinPrint_Element_Value: accessed-variable=BsShare_SwUpdFotaFinPrint_Element.Value
              SEND_BsShare_SwUpdFotaMode_Element_Value: accessed-variable=BsShare_SwUpdFotaMode_Element.Value
              SEND_BsShare_SwUpdFotaStatus_Element_Value: accessed-variable=BsShare_SwUpdFotaStatus_Element.Value
              SEND_BsShare_SwUpdFotadecrypt_Element_Value: accessed-variable=BsShare_SwUpdFotadecrypt_Element.Value
              SEND_BsShare_SwUpdReflash_Element_Value: accessed-variable=BsShare_SwUpdReflash_Element.Value
              SEND_BsShare_VehicleConfig_Element_Value: accessed-variable=BsShare_VehicleConfig_Element.Value
              SEND_BsShare_VisMeet_Element_Value: accessed-variable=BsShare_VisMeet_Element.Value
              SEND_RefCys_Certicificate1_Element_Value: accessed-variable=RefCys_Certicificate1_Element.Value
              SEND_RefCys_Certicificate_Element_Value: accessed-variable=RefCys_Certicificate_Element.Value
        MemAbstractMdl_NotifyJobEnd_BsConst_Audio
        MemAbstractMdl_NotifyJobEnd_BsConst_Communication
        MemAbstractMdl_NotifyJobEnd_BsConst_EngOffTimer
        MemAbstractMdl_NotifyJobEnd_BsConst_FuelGauge
        MemAbstractMdl_NotifyJobEnd_BsConst_Illumination
        MemAbstractMdl_NotifyJobEnd_BsConst_OilGauge
        MemAbstractMdl_NotifyJobEnd_BsConst_Power
        MemAbstractMdl_NotifyJobEnd_BsConst_PowerGauge
        MemAbstractMdl_NotifyJobEnd_BsConst_RealTimeClock
        MemAbstractMdl_NotifyJobEnd_BsConst_ServiceReminder
        MemAbstractMdl_NotifyJobEnd_BsConst_SpeedoGauge
        MemAbstractMdl_NotifyJobEnd_BsConst_TachoGauge
        MemAbstractMdl_NotifyJobEnd_BsConst_TempGauge
        MemAbstractMdl_NotifyJobEnd_BsConst_TripComputer
        MemAbstractMdl_NotifyJobEnd_BsConst_Warning
        MemAbstractMdl_NotifyJobEnd_BsCys_Certicificate
        MemAbstractMdl_NotifyJobEnd_BsDiag_Dtc
        MemAbstractMdl_NotifyJobEnd_BsDiag_ErrorRecord
        MemAbstractMdl_NotifyJobEnd_BsFuSa_Audio
        MemAbstractMdl_NotifyJobEnd_BsFuSa_Communication
        MemAbstractMdl_NotifyJobEnd_BsFuSa_Config
        MemAbstractMdl_NotifyJobEnd_BsFuSa_Display
        MemAbstractMdl_NotifyJobEnd_BsFuSa_Power
        MemAbstractMdl_NotifyJobEnd_BsFuSa_Warning
        MemAbstractMdl_NotifyJobEnd_BsFusa_Fota
        MemAbstractMdl_NotifyJobEnd_BsReten_Audio
        MemAbstractMdl_NotifyJobEnd_BsReten_Communication
        MemAbstractMdl_NotifyJobEnd_BsReten_Display
        MemAbstractMdl_NotifyJobEnd_BsReten_Gauges
        MemAbstractMdl_NotifyJobEnd_BsReten_Illumination
        MemAbstractMdl_NotifyJobEnd_BsReten_Odometer
        MemAbstractMdl_NotifyJobEnd_BsReten_Personalization
        MemAbstractMdl_NotifyJobEnd_BsReten_Power
        MemAbstractMdl_NotifyJobEnd_BsReten_RealTimeClock
        MemAbstractMdl_NotifyJobEnd_BsReten_Tripcomputer
        MemAbstractMdl_NotifyJobEnd_BsReten_VisDlt
        MemAbstractMdl_NotifyJobEnd_BsReten_Warning
        MemAbstractMdl_NotifyJobEnd_BsRt_CusDlt
        MemAbstractMdl_NotifyJobEnd_BsRt_FuelGauge
        MemAbstractMdl_NotifyJobEnd_BsRt_Illumination
        MemAbstractMdl_NotifyJobEnd_BsRt_Odometer
        MemAbstractMdl_NotifyJobEnd_BsRt_OilGauge
        MemAbstractMdl_NotifyJobEnd_BsRt_Personalization
        MemAbstractMdl_NotifyJobEnd_BsRt_PowerGauge
        MemAbstractMdl_NotifyJobEnd_BsRt_RealTimeClock
        MemAbstractMdl_NotifyJobEnd_BsRt_SpeedoGauge
        MemAbstractMdl_NotifyJobEnd_BsRt_TachoGauge
        MemAbstractMdl_NotifyJobEnd_BsRt_TempGauge
        MemAbstractMdl_NotifyJobEnd_BsRt_TripComputer
        MemAbstractMdl_NotifyJobEnd_BsRt_Warning
        MemAbstractMdl_NotifyJobEnd_BsShare_EcuPartNumber
        MemAbstractMdl_NotifyJobEnd_BsShare_SwUpdFotaFinPrint
        MemAbstractMdl_NotifyJobEnd_BsShare_SwUpdFotaMode
        MemAbstractMdl_NotifyJobEnd_BsShare_SwUpdFotaStatus
        MemAbstractMdl_NotifyJobEnd_BsShare_SwUpdFotadecrypt
        MemAbstractMdl_NotifyJobEnd_BsShare_SwUpdReflash
        MemAbstractMdl_NotifyJobEnd_BsShare_VehicleConfig
        MemAbstractMdl_NotifyJobEnd_BsShare_VisMeet
        MemAbstractMdl_NotifyJobEnd_RefCys_Certicificate
        MemAbstractMdl_NotifyJobEnd_RefCys_Certicificate1
  swc implementation MemAbstractStub_Implementation: behavior=MemAbstractStub_InternalBehavior
    code-descriptors:
      code Default: artifact-descriptors=autosar-engineering-object=category=SWSRC
